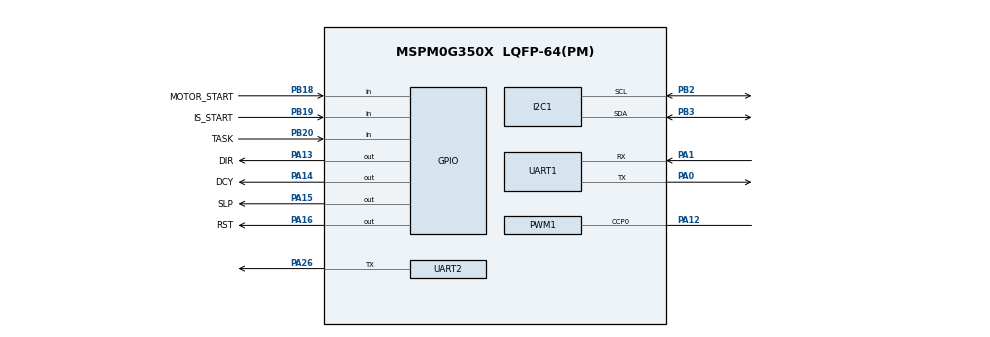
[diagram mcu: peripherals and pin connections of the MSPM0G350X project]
/**
 * @cliArgs --device "MSPM0G350X" --part "Default" --package "LQFP-64(PM)" --product "mspm0_sdk@2.11.00.07"
 * @versions {"tool":"1.26.2+4477"}
 */

/**
 * Import the modules used in this configuration.
 */
const GPIO   = scripting.addModule("/ti/driverlib/GPIO", {}, false);
const GPIO1  = GPIO.addInstance();
const GPIO2  = GPIO.addInstance();
const I2C    = scripting.addModule("/ti/driverlib/I2C", {}, false);
const I2C1   = I2C.addInstance();
const PWM    = scripting.addModule("/ti/driverlib/PWM", {}, false);
const PWM1   = PWM.addInstance();
const SYSCTL = scripting.addModule("/ti/driverlib/SYSCTL");
const TIMER  = scripting.addModule("/ti/driverlib/TIMER", {}, false);
const TIMER1 = TIMER.addInstance();
const UART   = scripting.addModule("/ti/driverlib/UART", {}, false);
const UART1  = UART.addInstance();
const UART2  = UART.addInstance();

/**
 * Write custom configuration values to the imported modules.
 */
const divider9       = system.clockTree["UDIV"];
divider9.divideValue = 2;

const multiplier2         = system.clockTree["PLL_QDIV"];
multiplier2.multiplyValue = 5;

const mux4       = system.clockTree["EXHFMUX"];
mux4.inputSelect = "EXHFMUX_XTAL";

const mux8       = system.clockTree["HSCLKMUX"];
mux8.inputSelect = "HSCLKMUX_SYSPLL0";

const pinFunction4     = system.clockTree["HFXT"];
pinFunction4.inputFreq = 40;
pinFunction4.enable    = true;

GPIO1.$name                         = "MOTOR";
GPIO1.associatedPins.create(4);
GPIO1.associatedPins[0].$name       = "DIR";
GPIO1.associatedPins[0].pin.$assign = "PA13";
GPIO1.associatedPins[1].$name       = "DCY";
GPIO1.associatedPins[1].pin.$assign = "PA14";
GPIO1.associatedPins[2].$name       = "SLP";
GPIO1.associatedPins[2].pin.$assign = "PA15";
GPIO1.associatedPins[3].$name       = "RST";
GPIO1.associatedPins[3].pin.$assign = "PA16";

const Board = scripting.addModule("/ti/driverlib/Board", {}, false);

GPIO2.$name                              = "KEY";
GPIO2.associatedPins.create(3);
GPIO2.associatedPins[0].direction        = "INPUT";
GPIO2.associatedPins[0].internalResistor = "PULL_DOWN";
GPIO2.associatedPins[0].$name            = "TASK";
GPIO2.associatedPins[0].pin.$assign      = "PB20";
GPIO2.associatedPins[1].direction        = "INPUT";
GPIO2.associatedPins[1].internalResistor = "PULL_DOWN";
GPIO2.associatedPins[1].$name            = "IS_START";
GPIO2.associatedPins[1].pin.$assign      = "PB19";
GPIO2.associatedPins[2].direction        = "INPUT";
GPIO2.associatedPins[2].internalResistor = "PULL_DOWN";
GPIO2.associatedPins[2].$name            = "MOTOR_START";
GPIO2.associatedPins[2].pin.$assign      = "PB18";

I2C1.$name                             = "OLED";
I2C1.basicEnableController             = true;
I2C1.advDigitalGlitchFilter            = "CLOCKS_1";
I2C1.advControllerRXFIFOTRIG           = "BYTES_8";
I2C1.advControllerTXFIFOTRIG           = "BYTES_7";
I2C1.enableDMAEvent1                   = false;
I2C1.enableDMAEvent2                   = false;
I2C1.peripheral.$assign                = "I2C1";
I2C1.peripheral.sdaPin.$assign         = "PB3";
I2C1.peripheral.sclPin.$assign         = "PB2";
I2C1.sdaPinConfig.$name                = "ti_driverlib_gpio_GPIOPinGeneric0";
I2C1.sdaPinConfig.hideOutputInversion  = scripting.forceWrite(false);
I2C1.sdaPinConfig.onlyInternalResistor = scripting.forceWrite(false);
I2C1.sdaPinConfig.passedPeripheralType = scripting.forceWrite("Digital");
I2C1.sclPinConfig.$name                = "ti_driverlib_gpio_GPIOPinGeneric1";
I2C1.sclPinConfig.hideOutputInversion  = scripting.forceWrite(false);
I2C1.sclPinConfig.onlyInternalResistor = scripting.forceWrite(false);
I2C1.sclPinConfig.passedPeripheralType = scripting.forceWrite("Digital");

PWM1.$name                              = "MOTOR_PWM";
PWM1.ccIndex                            = [0];
PWM1.clockDivider                       = 8;
PWM1.timerCount                         = 10000;
PWM1.pwmMode                            = "EDGE_ALIGN_UP";
PWM1.interrupts                         = ["LOAD_EVENT"];
PWM1.PWM_CHANNEL_0.$name                = "ti_driverlib_pwm_PWMTimerCC0";
PWM1.PWM_CHANNEL_0.ccValue              = 5000;
PWM1.PWM_CHANNEL_0.dutyCycle            = 50;
PWM1.ccp0PinConfig.direction            = scripting.forceWrite("OUTPUT");
PWM1.ccp0PinConfig.hideOutputInversion  = scripting.forceWrite(false);
PWM1.ccp0PinConfig.onlyInternalResistor = scripting.forceWrite(false);
PWM1.ccp0PinConfig.passedPeripheralType = scripting.forceWrite("Digital");
PWM1.ccp0PinConfig.$name                = "ti_driverlib_gpio_GPIOPinGeneric3";
PWM1.peripheral.$assign                 = "TIMG0";
PWM1.peripheral.ccp0Pin.$assign         = "PA12";

SYSCTL.forceDefaultClkConfig = true;
SYSCTL.clockTreeEn           = true;

/* 10 ms application timebase: key debounce, 2 s long press and UI pacing. */
TIMER1.$name              = "APP_TICK";
TIMER1.timerClkSrc        = "LFCLK";
TIMER1.timerMode          = "PERIODIC";
TIMER1.timerPeriod        = "10 ms";
TIMER1.interrupts         = ["ZERO"];
TIMER1.timerStartTimer    = true;
TIMER1.peripheral.$assign = "TIMG8";

UART1.$name                            = "K230";
UART1.rxFifoThreshold                  = "DL_UART_RX_FIFO_LEVEL_ONE_ENTRY";
UART1.txFifoThreshold                  = "DL_UART_TX_FIFO_LEVEL_ONE_ENTRY";
UART1.enableFIFO                       = true;
UART1.enableDMARX                      = false;
UART1.enableDMATX                      = false;
UART1.enabledInterrupts                = ["RX"];
UART1.targetBaudRate                   = 115200;
UART1.peripheral.$assign               = "UART0";
UART1.peripheral.rxPin.$assign         = "PA1";
UART1.peripheral.txPin.$assign         = "PA0";
UART1.txPinConfig.direction            = scripting.forceWrite("OUTPUT");
UART1.txPinConfig.hideOutputInversion  = scripting.forceWrite(false);
UART1.txPinConfig.onlyInternalResistor = scripting.forceWrite(false);
UART1.txPinConfig.passedPeripheralType = scripting.forceWrite("Digital");
UART1.txPinConfig.$name                = "K230_UART_TX_PIN";
UART1.rxPinConfig.hideOutputInversion  = scripting.forceWrite(false);
UART1.rxPinConfig.onlyInternalResistor = scripting.forceWrite(false);
UART1.rxPinConfig.passedPeripheralType = scripting.forceWrite("Digital");
UART1.rxPinConfig.$name                = "K230_UART_RX_PIN";

UART2.$name                            = "DEBUG";
UART2.targetBaudRate                   = 115200;
UART2.enableFIFO                       = true;
/*
 * UART3/PA26 is the K230-to-PC forwarding channel.  Its TX interrupt must
 * occur after the hardware has consumed the bytes already in the FIFO; using
 * the EMPTY level makes the software refill operation unambiguous.
 */
UART2.txFifoThreshold                  = "DL_UART_TX_FIFO_LEVEL_EMPTY";
UART2.peripheral.txPin.$assign         = "PA26";
UART2.txPinConfig.$name                = "ti_driverlib_gpio_GPIOPinGeneric2";
UART2.txPinConfig.direction            = scripting.forceWrite("OUTPUT");
UART2.txPinConfig.hideOutputInversion  = scripting.forceWrite(false);
UART2.txPinConfig.onlyInternalResistor = scripting.forceWrite(false);
UART2.txPinConfig.passedPeripheralType = scripting.forceWrite("Digital");
UART2.rxPinConfig.$name                = "ti_driverlib_gpio_GPIOPinGeneric4";
UART2.rxPinConfig.hideOutputInversion  = scripting.forceWrite(false);
UART2.rxPinConfig.onlyInternalResistor = scripting.forceWrite(false);
UART2.rxPinConfig.passedPeripheralType = scripting.forceWrite("Digital");

/**
 * Pinmux solution for unlocked pins/peripherals. This ensures that minor changes to the automatic solver in a future
 * version of the tool will not impact the pinmux you originally saw.  These lines can be completely deleted in order to
 * re-solve from scratch.
 */
pinFunction4.peripheral.$suggestSolution           = "SYSCTL";
pinFunction4.peripheral.hfxInPin.$suggestSolution  = "PA5";
pinFunction4.peripheral.hfxOutPin.$suggestSolution = "PA6";
Board.peripheral.$suggestSolution                  = "DEBUGSS";
Board.peripheral.swclkPin.$suggestSolution         = "PA20";
Board.peripheral.swdioPin.$suggestSolution         = "PA19";
UART2.peripheral.$suggestSolution                  = "UART3";
UART2.peripheral.rxPin.$suggestSolution            = "PA25";
